# ECAP_ECAP_50240000h register map
Vendor: Texas Instruments
Peripheral module from a debugger description file (folder AM261x).
Registers are 32-bit, read-write, reset 0x0 unless marked. A register's access mark holds for its fields unless they carry their own. Offsets are as the file gives them; lines under a group give offsets from that group; [hi:lo] are bit positions; {n}, {i} and the like mark numbered series; 'fields as' and 'values as' point back to an identical list; <NAME> marks a mode.

## ECAP
0x00 ECAP_TSCTR — Time-Stamp Counter.
  [31:0] TSCTR — Active 32-bit counter register that is used as the capture time-base HR mode : 1] This register reads HRCOUNTER value and is not writable 2] can be reset using CTRFILTRESET 3] Its not synchronized to SYSCLK domain so reads may not be accurate
0x04 ECAP_CTRPHS — Counter Phase Offset Value Register.
  [31:0] CTRPHS — Counter phase value register that can be programmed for phase lag/lead. This register CTRPHS is loaded into TSCTR upon either a SYNCI event or S/W force via a control bit. Used to achieve phase control synchronization with respect to other eCAP and EPWM time-bases. This register is not applicable in HR mode.
0x08 ECAP_CAP1 — Capture 1 Register.
  [31:0] CAP1 — This register can be loaded (written) by:1. Time-Stamp (counter value) during a capture event.2. Software - may be useful for test purposes/initialization.3. APRD shadow register (ECAP_CAP3) when used in APWM mode.
0x0C ECAP_CAP2 — Capture 2 Register.
  [31:0] CAP2 — This register can be loaded (written) by:1. Time-Stamp (counter value) during a capture event.2. Software - may be useful for test purposes.3. ACMP shadow register (ECAP_CAP4) when used in APWM mode.
0x10 ECAP_CAP3 — Capture 3 Register.
  [31:0] CAP3 — In CMP mode this is a time-stamp capture register.In APMW mode this is the period shadow (APER) register.User updates the PWM period value via this register.In this mode the ECAP_CAP3 (APRD) register shadows the ECAP_CAP1 register.
0x14 ECAP_CAP4 — Capture 4 Register.
  [31:0] CAP4 — In CMP mode this is a time-stamp capture register.In APMW mode this is the compare shadow (ACMP) register.User updates the PWM Compare value via this register.In this mode the ECAP_CAP4 (ACMP) register shadows the ECAP_CAP2 register.
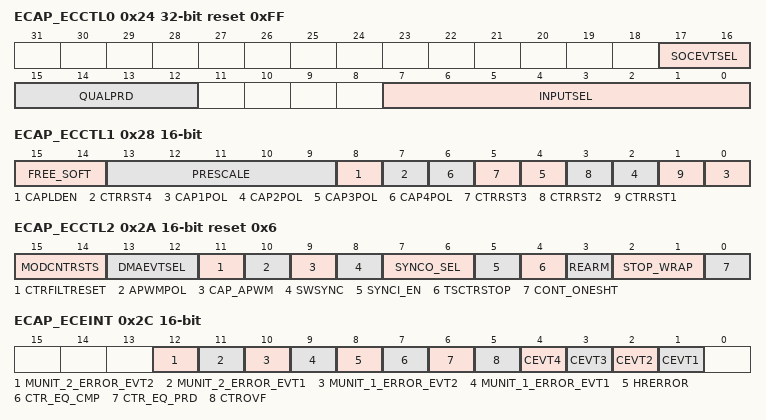
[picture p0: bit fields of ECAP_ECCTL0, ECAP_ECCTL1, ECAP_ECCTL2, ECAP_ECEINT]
0x24 ECAP_ECCTL0 reset 0xFF — Capture Control Register 0
  [17:16] SOCEVTSEL — ADC SOC event select Capture Mode: 00b[R/W] = SOC trigger source is CEVT1 01b[R/W] = SOC trigger source is CEVT2 10b[R/W] = SOC trigger source is CEVT3 11b[R/W] = SOC trigger source is CEVT4 APWM Mode: 00b[R/W] = SOC trigger interrupt source is period match 01b[R/W] = SOC trigger interrupt source is compare match 10b[R/W] = SOC trigger interrupt source is period match or compare match 11b[R/W] = Disabled
  [15:12] QUALPRD — Qual period to filter out noise on input signals being monitored, Not applicable for HR mode. 0x0 : Bypass 0x1 : pulses of with 1 cycle or less will be filtered out 0x2 : pulses of with 2 cycles or less will be filtered out .... 0xF : pulses of with 15 cycles or less will be filtered out
  [7:0] INPUTSEL — Capture input source select bits 0x0 capture input is ECAPxINPUT[0] 0x1 capture input is ECAPxINPUT[1] 0x2 capture input is ECAPxINPUT[2] ... 0xFF capture input is ECAPxINPUT[256]
0x28 ECAP_ECCTL1 16-bit — Capture Control Register 1
  [15:14] FREE_SOFT — Emulation Control 0 TSCTR counter stops immediately on emulation suspend1 TSCTR counter runs until = 02 TSCTR counter is unaffected by emulation suspend (Run Free)3 TSCTR counter is unaffected by emulation suspend (Run Free)
  [13:9] PRESCALE — Event Filter prescale select 0 Divide by 1 (i.e,. no prescale, by-pass the prescaler)1 Divide by 22 Divide by 43 Divide by 64 Divide by 85 Divide by 1030 Divide by 6031 Divide by 62
  [8] CAPLDEN — Enable Loading of CAP1-4 registers on a capture event. Note that this bit does not disable CEVTn events from being generated. 0 Disable CAP1-4 register loads at capture event time.1 Enable CAP1-4 register loads at capture event time.
  [7] CTRRST4 — Counter Reset on Capture Event 4 0 Do not reset counter on Capture Event 4 (absolute time stamp operation)1 Reset counter after Capture Event 4 time- stamp has been captured (used in difference mode operation)
  [2n-2] CAP{n}POL (n=1..4) — Capture Event {n} Polarity select 0 Capture Event {n} triggered on a rising edge (RE)1 Capture Event {n} triggered on a falling edge (FE)
  [5] CTRRST3 — Counter Reset on Capture Event 3 0 Do not reset counter on Capture Event 3 (absolute time stamp)1 Reset counter after Event 3 time-stamp has been captured (used in difference mode operation)
  [3] CTRRST2 — Counter Reset on Capture Event 2 0 Do not reset counter on Capture Event 2 (absolute time stamp)1 Reset counter after Event 2 time-stamp has been captured (used in difference mode operation)
  [1] CTRRST1 — Counter Reset on Capture Event 1 0 Do not reset counter on Capture Event 1 (absolute time stamp)1 Reset counter after Event 1 time-stamp has been captured (used in difference mode operation)
0x2A ECAP_ECCTL2 16-bit access not given reset 0x6 — Capture Control Register 2
  [15:14] MODCNTRSTS rw — This bit field reads current status on modulo counter 00b[R] = CAP1 register gets loaded on next capture event. 01b[R] = CAP2 register gets loaded on next capture event. 10b[R] = CAP3 register gets loaded on next capture event. 11b[R] = CAP4 register gets loaded on next capture event.
  [13:12] DMAEVTSEL rw — DMA event select Capture Mode: 00b[R/W] = DMA interrupt source is CEVT1 01b[R/W] = DMA interrupt source is CEVT2 10b[R/W] = DMA interrupt source is CEVT3 11b[R/W] = DMA interrupt source is CEVT4 APWM Mode: 00b[R/W] = DMA interrupt source is period match 01b[R/W] = DMA interrupt source is compare match 10b[R/W] = DMA interrupt source is period match or compare match 11b[R/W] = Disabled
  [11] CTRFILTRESET — Reset Bit 0h[R] = No effect 1h[W] = Resets event filter, counter, modulo counter and CEVT[1,2,3,4] and CNTOVF , HRERROR flags Note: This provides an ability start capture module from known state in case spurious inputs are captured while ECAP is configured. (access R/W1TC)
  [10] APWMPOL rw — APWM output polarity select. This is applicable only in APWM operating mode. 0 Output is active high (Compare value defines high time)1 Output is active low (Compare value defines low time)
  [9] CAP_APWM rw — CAP/APWM operating mode select 0 ECAP module operates in capture mode. This mode forces the following configuration: - Inhibits TSCTR resets via CTR = PRD event - Inhibits shadow loads on CAP1 and 2 registers - Permits user to enable CAP1-4 register load - CAPx/APWMx pin operates as a capture input1 ECAP module operates in APWM mode. This mode forces the following configuration: - Resets TSCTR on CTR = PRD event (period boundary ) - Permits shadow loading on CAP1 and 2 registers - Disables loading of time-stamps into CAP1-4 registers - CAPx/APWMx pin operates as a APWM output
  [8] SWSYNC — Software-forced Counter [TSCTR] Synchronizer. This provides the user a method to generate a synchronization pulse through software. In APWM mode, the synchronization pulse can also be sourced from the CTR = PRD event. 0 Writing a zero has no effect. Reading always returns a zero1 Writing a one forces a TSCTR shadow load of current ECAP module and any ECAP modules down-stream providing the SYNCO_SEL bits are 0,0. After writing a 1, this bit returns to a zero. Note: Selection CTR = PRD is meaningful only in APWM mode; however, you can choose it in CAP mode if you find doing so useful. (access R/W1TS)
  [7:6] SYNCO_SEL rw — Sync-Out Select 0 sync out signal is SWSYNC1 Select CTR = PRD event to be the sync-out signal3 Disable sync out signal
  [5] SYNCI_EN rw — Counter [TSCTR] Sync-In select mode 0 Disable sync-in option1 Enable counter (TSCTR) to be loaded from CTRPHS register upon either a SYNCI signal or a S/W force event.
  [4] TSCTRSTOP rw — Time Stamp [TSCTR] Counter Stop [freeze] Control 0 TSCTR stopped1 TSCTR free-running
  [3] REARM — Re-Arming Control. Note: The re-arm function is valid in one shot or continuous mode 0 Has no effect (reading always returns a 0)1 Arms the one-shot sequence as follows: (1) Resets the Mod4 counter to zero (2) Unfreezes the Mod4 counter (3) Enables capture register loads (access R/W1TS)
  [2:1] STOP_WRAP rw — Stop value for one-shot mode. This is the number [between 1-4] of captures allowed to occur before the CAP[1-4] registers are frozen, that is, capture sequence is stopped. Wrap value for continuous mode. This is the number [between 1-4] of the capture register in which the circular buffer wraps around and starts again. Notes: STOP_WRAP is compared to Mod4 counter and, when equal, 2 actions occur: - Mod4 counter is stopped [frozen] - Capture register loads are inhibited In one-shot mode, further interrupt events are blocked until re-armed. 0 Stop after Capture Event 1 in one-shot mode Wrap after Capture Event 1 in continuous mode.1 Stop after Capture Event 2 in one-shot mode Wrap after Capture Event 2 in continuous mode.2 Stop after Capture Event 3 in one-shot mode Wrap after Capture Event 3 in continuous mode.3 Stop after Capture Event 4 in one-shot mode Wrap after Capture Event 4 in continuous mode.
  [0] CONT_ONESHT rw — Continuous or one-shot mode control [applicable only in capture mode] 0 Operate in continuous mode1 Operate in one-Shot mode
0x2C ECAP_ECEINT 16-bit — The interrupt enable bits (CEVT1, ...) block any of the selected events from generating an interrupt. Events will still be latched into the flag bit (ECFLG register) and can be forced/cleared via the ECFRC/ECCLR registers. The proper procedure for configuring peripheral modes and interrupts is as follows: - Disable global interrupts - Stop eCAP counter - Disable eCAP interrupts - Configure peripheral registers - Clear spurious eCAP interrupt flags - Enable eCAP interrupts - Start eCAP counter - Enable global interrupts.
  [12] MUNIT_2_ERROR_EVT2 — Monitoring unit 2 error event 2 interrupt enable 0 : Disable Monitoring unit 2 error event 2 interrupt 1 : Enable Monitoring unit 2 error event 2 interrupt
  [11] MUNIT_2_ERROR_EVT1 — Monitoring unit 2 error event 2 interrupt enable 0 : Disable Monitoring unit 2 error event 1 interrupt 1 : Enable Monitoring unit 2 error event 1 interrupt
  [10] MUNIT_1_ERROR_EVT2 — Monitoring unit 1 error event 1 interrupt enable 0 : Disable Monitoring unit 1 error event 2 interrupt 1 : Enable Monitoring unit 1 error event 2 interrupt
  [9] MUNIT_1_ERROR_EVT1 — Monitoring unit 1 error event 1 interrupt enable 0 : Disable Monitoring unit 1 error event 1 interrupt 1 : Enable Monitoring unit 1 error event 1 interrupt
  [8] HRERROR — High resolution error interrupt enable 0 Disable High Resolution Error as an Interrupt source1 Enable High Resolution Error as an Interrupt source
  [7] CTR_EQ_CMP — Counter Equal Compare Interrupt Enable 0 Disable Compare Equal as an Interrupt source1 Enable Compare Equal as an Interrupt source
  [6] CTR_EQ_PRD — Counter Equal Period Interrupt Enable 0 Disable Period Equal as an Interrupt source1 Enable Period Equal as an Interrupt source
  [5] CTROVF — Counter Overflow Interrupt Enable 0 Disabled counter Overflow as an Interrupt source1 Enable counter Overflow as an Interrupt source
  [4] CEVT4 — Capture Event 4 Interrupt Enable 0 Disable Capture Event 4 as an Interrupt source1 Capture Event 4 Interrupt Enable
  [3] CEVT3 — Capture Event 3 Interrupt Enable 0 Disable Capture Event 3 as an Interrupt source1 Enable Capture Event 3 as an Interrupt source
  [2] CEVT2 — Capture Event 2 Interrupt Enable 0 Disable Capture Event 2 as an Interrupt source1 Enable Capture Event 2 as an Interrupt source
  [1] CEVT1 — Capture Event 1 Interrupt Enable 0 Disable Capture Event 1 as an Interrupt source1 Enable Capture Event 1 as an Interrupt source
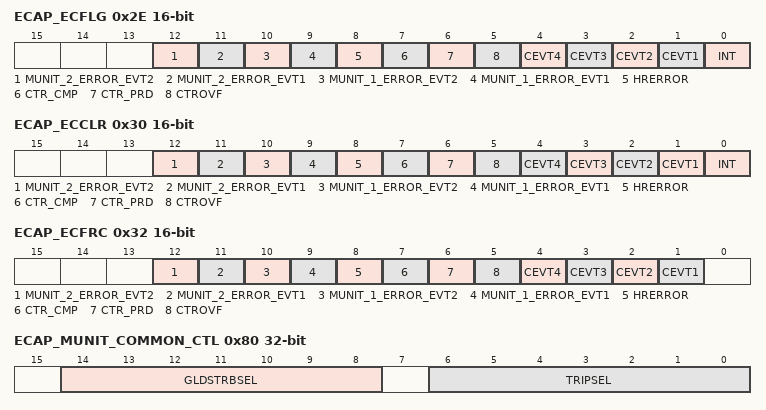
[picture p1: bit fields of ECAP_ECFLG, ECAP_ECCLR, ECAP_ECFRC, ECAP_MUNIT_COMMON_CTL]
0x2E ECAP_ECFLG 16-bit ro — Capture Interrupt Flag Register.
  [12] MUNIT_2_ERROR_EVT2 — Error event 2 Interrupt Flag from monitoring unit 2
  [11] MUNIT_2_ERROR_EVT1 — Error event 2 Interrupt Flag from monitoring unit 2
  [10] MUNIT_1_ERROR_EVT2 — Error event 2 Interrupt Flag from monitoring unit 1
  [9] MUNIT_1_ERROR_EVT1 — Error event 2 Interrupt Flag from monitoring unit 1
  [8] HRERROR — High resolution error status flag 0 Indicates no event occurred1 Indicates the High resolution Error occurred
  [7] CTR_CMP — Compare Equal Compare Status Flag. This flag is active only in APWM mode. 0 Indicates no event occurred1 Indicates the counter (TSCTR) reached the compare register value (ACMP)
  [6] CTR_PRD — Counter Equal Period Status Flag. This flag is only active in APWM mode. 0 Indicates no event occurred1 Indicates the counter (TSCTR) reached the period register value (APRD) and was reset.
  [5] CTROVF — Counter Overflow Status Flag. This flag is active in CAP and APWM mode. 0 Indicates no event occurred1 Indicates the counter (TSCTR) has made the transition from FFFFFFFF to 00000000
  [4] CEVT4 — Capture Event 4 Status Flag This flag is only active in CAP mode. 0 Indicates no event occurred1 Indicates the fourth event occurred at ECAPx pin
  [3] CEVT3 — Capture Event 3 Status Flag. This flag is active only in CAP mode. 0 Indicates no event occurred1 Indicates the third event occurred at ECAPx pin.
  [2] CEVT2 — Capture Event 2 Status Flag. This flag is only active in CAP mode. 0 Indicates no event occurred1 Indicates the second event occurred at ECAPx pin.
  [1] CEVT1 — Capture Event 1 Status Flag. This flag is only active in CAP mode. 0 Indicates no event occurred1 Indicates the first event occurred at ECAPx pin.
  [0] INT — Global Interrupt Status Flag 0 Indicates no event occurred1 Indicates that an interrupt was generated.
0x30 ECAP_ECCLR 16-bit access not given — Capture Interrupt Clear Register.
  [12] MUNIT_2_ERROR_EVT2 — Writing '1' clears MUNIT_2_ERROR_EVT2 interrupt flag (access R/W1TC)
  [11] MUNIT_2_ERROR_EVT1 — Writing '1' clears MUNIT_2_ERROR_EVT1 interrupt flag (access R/W1TC)
  [10] MUNIT_1_ERROR_EVT2 — Writing '1' clears MUNIT_1_ERROR_EVT2 interrupt flag (access R/W1TC)
  [9] MUNIT_1_ERROR_EVT1 — Writing '1' clears MUNIT_1_ERROR_EVT1 interrupt flag (access R/W1TC)
  [8] HRERROR — High resolution error status Clear 0 Writing a 0 has no effect. Always reads back a 01 Writing a 1 clears the HRERROR flag. (access R/W1TC)
  [7] CTR_CMP — Counter Equal Compare Status Clear 0 Writing a 0 has no effect. Always reads back a 01 Writing a 1 clears the CTR=CMP flag. (access R/W1TC)
  [6] CTR_PRD — Counter Equal Period Status Clear 0 Writing a 0 has no effect. Always reads back a 01 Writing a 1 clears the CTR=PRD flag. (access R/W1TC)
  [5] CTROVF — Counter Overflow Status Clear 0 Writing a 0 has no effect. Always reads back a 01 Writing a 1 clears the CTROVF flag. (access R/W1TC)
  [n] CEVT{n} (n=1..4) — Capture Event {n} Status Clear 0 Writing a 0 has no effect. Always reads back a 01 Writing a 1 clears the CEVT{n} flag. (access R/W1TC)
  [0] INT — ECAP Global Interrupt Status Clear 0 Writing a 0 has no effect. Always reads back a 01 Writing a 1 clears the INT flag and enable further interrupts to be generated if any of the event flags are set to 1 (access R/W1TC)
0x32 ECAP_ECFRC 16-bit access not given — Capture Interrupt Force Register.
  [12] MUNIT_2_ERROR_EVT2 — Writing '1' sets MUNIT_2_ERROR_EVT2 interrupt flag (access R/W1TS)
  [11] MUNIT_2_ERROR_EVT1 — Writing '1' sets MUNIT_2_ERROR_EVT1 interrupt flag (access R/W1TS)
  [10] MUNIT_1_ERROR_EVT2 — Writing '1' sets MUNIT_1_ERROR_EVT2 interrupt flag (access R/W1TS)
  [9] MUNIT_1_ERROR_EVT1 — Writing '1' sets MUNIT_1_ERROR_EVT1 interrupt flag (access R/W1TS)
  [8] HRERROR — High resolution error Force interrupt 0 No effect. Always reads back a 0.1 Writing a 1 sets the CTR_CMP flag. (access R/W1TS)
  [7] CTR_CMP — Force Counter Equal Compare Interrupt. This event is only active in APWM mode. 0 No effect. Always reads back a 0.1 Writing a 1 sets the CTR_CMP flag. (access R/W1TS)
  [6] CTR_PRD — Force Counter Equal Period Interrupt. This event is only active in APWM mode. 0 No effect. Always reads back a 0.1 Writing a 1 sets the CTR_PRD flag. (access R/W1TS)
  [5] CTROVF — Force Counter Overflow 0 No effect. Always reads back a 0.1 Writing a 1 to this bit sets the CTROVF flag. (access R/W1TS)
  [4] CEVT4 — Force Capture Event 4. This event is only active in CAP mode. 0 No effect. Always reads back a 0.1 Writing a 1 sets the CEVT4 flag. (access R/W1TS)
  [3] CEVT3 — Force Capture Event 3. This event is only active in CAP mode. 0 No effect. Always reads back a 0.1 Writing a 1 sets the CEVT3 flag. (access R/W1TS)
  [2] CEVT2 — Force Capture Event 2. This event is only active in CAP mode. 0 No effect. Always reads back a 0.1 Writing a 1 sets the CEVT2 flag. (access R/W1TS)
  [1] CEVT1 — Force Capture Event 1. This event is only active in CAP mode. 0 No effect. Always reads back a 0.1 Sets the CEVT1 flag. (access R/W1TS)
0x3C ECAP_ECAPSYNCINSEL reset 0x1 — SYNC source select register.
  [6:0] SEL — These bits determine the source of SYNCIN signal. 0x0 : Reserved. 0x1: EPWM0.SYNCOUT 0x1: EPWM1.SYNCOUT 0x3: EPWM2.SYNCOUT ... 0x32: EPWM31.SYNCOUT 0x33-0x128: Reserved
0x80 ECAP_MUNIT_COMMON_CTL — Control registers for monitoring unit {#}
  [14:8] GLDSTRBSEL — Global load strobe select to enable shadow to active loading 0x0 : Reserved. 0x1 to 0x7F : Global load strobe from SOC level including EPWM global load strobes.
  [6:0] TRIPSEL — Trip signal select to disable and enable signal monitoring automatically 0x0 : Disabled, Trip signals does not effect signal monitoring. 0x1 to 0x7F : Signal monioring is disabled when selected signal is high and enabled when it is low
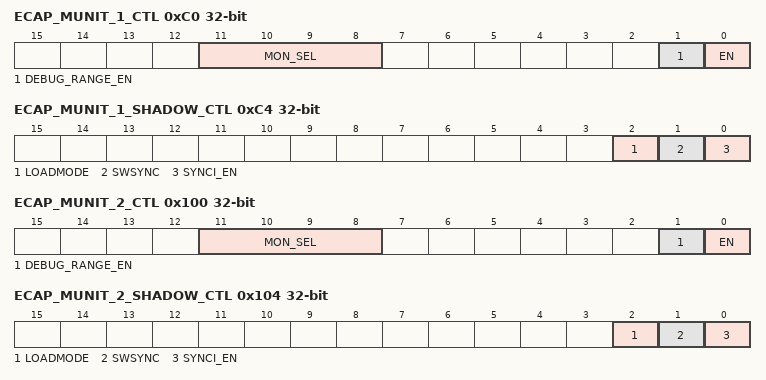
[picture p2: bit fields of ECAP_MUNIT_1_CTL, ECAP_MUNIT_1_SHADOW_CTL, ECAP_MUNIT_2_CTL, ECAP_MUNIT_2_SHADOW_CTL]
0xC0 ECAP_MUNIT_1_CTL — Control registers for monitoring unit 1
  [11:8] MON_SEL — Type of monitoring 0 : High Pulse width 1 : Low Pulse width 2 : Period width from Rise to Rise 3 : Period width from fall to fall 4 : Monitor rise edge 5 : Monitor fall edge 615 : Reserved [High Pulse width]
  [1] DEBUG_RANGE_EN — Debug mode enable. 0 : Debug mode is disabled. 1 : Debug mode of monitoring unit 1 is enabled to obtain the variation seen in the system for debug purpose. Range is captured in MUNIT_1_DEBUG_RANGE_MIN and MUNIT_1_DEBUG_RANGE_MAX registers Toggle DEBUG_RANGE_EN to restart this process, this will initialize MUNIT_1_DEBUG_RANGE_MIN and MUNIT_1_DEBUG_RANGE_MAX registers.
  [0] EN — 0 : Monitoring unit 1 is disabled 1 : Monitoring unit 1 is enabled
0xC4 ECAP_MUNIT_1_SHADOW_CTL access not given — Shadow control registers for monitoring unit 1
  [2] LOADMODE rw — Load mode 0 : Active registers are loaded with shadow on next sync event 1 : Active registers are loaded with shadow on EPWMx.GLDLCSTRB event
  [1] SWSYNC — Copies Min and Max values from shadow to active registers immediately if MUNIT_1_SHADOW_CTL.SYNCI_EN is set. (access R/W1TS)
  [0] SYNCI_EN rw — Shadow Enable 0 : Disabled 1 : Enabled
0xD0 ECAP_MUNIT_1_MIN — Min value for monitoring unit 1
  [31:0] MIN_VALUE — Minimum value for monitoring
0xD4 ECAP_MUNIT_1_MAX — Max value for monitoring unit 1
  [31:0] MAX_VALUE — Maximum value for monitoring
0xD8 ECAP_MUNIT_1_MIN_SHADOW — Shadow register for Min value of monitoring unit 1
  [31:0] MIN_VALUE_SHADOW — Shadow minimum value for monitoring. Shadow value is loaded to active register on Sync event or global load strobe.
0xDC ECAP_MUNIT_1_MAX_SHADOW — Shadow register for Max value of monitoring unit 1
  [31:0] MAX_VALUE_SHADOW — Shadow maximum value for monitoring. Shadow value is loaded to active register on Sync event or global load strobe.
0xE0 ECAP_MUNIT_1_DEBUG_RANGE_MIN ro reset 0xFFFFFFFF — Observed Min value of check being enabled on minotoring unit 1
  [31:0] MIN_VALUE — Observed Min value of check being enabled on minotoring unit 1. Is updated when MUNIT_1_CTL.DEBUG_RANGE_EN is set to '1'
0xE4 ECAP_MUNIT_1_DEBUG_RANGE_MAX ro — Observed Max value of check being enabled on minotoring unit 1
  [31:0] MAX_VALUE — Observed Min value of check being enabled on minotoring unit 1. Is updated when MUNIT_1_CTL.DEBUG_RANGE_EN is set to '1'
0x100 ECAP_MUNIT_2_CTL — Control registers for monitoring unit 2
  [11:8] MON_SEL — Type of monitoring 0 : High Pulse width 1 : Low Pulse width 2 : Period width from Rise to Rise 3 : Period width from fall to fall 4 : Monitor rise edge 5 : Monitor fall edge 615 : Reserved [High Pulse width]
  [1] DEBUG_RANGE_EN — Debug mode enable. 0 : Debug mode is disabled. 1 : Debug mode of monitoring unit 2 is enabled to obtain the variation seen in the system for debug purpose. Range is captured in MUNIT_2_DEBUG_RANGE_MIN and MUNIT_2_DEBUG_RANGE_MAX registers Toggle DEBUG_RANGE_EN to restart this process, this will initialize MUNIT_2_DEBUG_RANGE_MIN and MUNIT_2_DEBUG_RANGE_MAX registers.
  [0] EN — 0 : Monitoring unit 2 is disabled 1 : Monitoring unit 2 is enabled
0x104 ECAP_MUNIT_2_SHADOW_CTL access not given — Shadow control registers for monitoring unit 2
  [2] LOADMODE rw — Load mode 0 : Active registers are loaded with shadow on next sync event 1 : Active registers are loaded with shadow on EPWMx.GLDLCSTRB event
  [1] SWSYNC — Copies Min and Max values from shadow to active registers immediately if MUNIT_2_SHADOW_CTL.SYNCI_EN is set. (access R/W1TS)
  [0] SYNCI_EN rw — Shadow Enable 0 : Disabled 1 : Enabled
0x110 ECAP_MUNIT_2_MIN — Min value for monitoring unit 2
  [31:0] MIN_VALUE — Minimum value for monitoring
0x114 ECAP_MUNIT_2_MAX — Max value for monitoring unit 2
  [31:0] MAX_VALUE — Maximum value for monitoring
0x118 ECAP_MUNIT_2_MIN_SHADOW — Shadow register for Min value of monitoring unit 2
  fields as ECAP_MUNIT_1_MIN_SHADOW
0x11C ECAP_MUNIT_2_MAX_SHADOW — Shadow register for Max value of monitoring unit 2
  fields as ECAP_MUNIT_1_MAX_SHADOW
0x120 ECAP_MUNIT_2_DEBUG_RANGE_MIN ro reset 0xFFFFFFFF — Observed Min value of check being enabled on minotoring unit 2
  [31:0] MIN_VALUE — Observed Min value of check being enabled on minotoring unit 2. Is updated when MUNIT_2_CTL.DEBUG_RANGE_EN is set to '1'
0x124 ECAP_MUNIT_2_DEBUG_RANGE_MAX ro — Observed Max value of check being enabled on minotoring unit 2
  [31:0] MAX_VALUE — Observed Min value of check being enabled on minotoring unit 2. Is updated when MUNIT_2_CTL.DEBUG_RANGE_EN is set to '1'
